# STM32WBA65 register map
File version: 1.0
CPU: CM33 r0p1, little endian, MPU, FPU, 4 interrupt priority bits
Registers are 32-bit, read-write, reset 0x0 unless marked. A register's access mark holds for its fields unless they carry their own. Offsets are from the block's base; [hi:lo] are bit positions.

## GTZC_TZSC — GTZC_TZSC address block description
Base 0x40032400
Same registers: SEC_GTZC_TZSC 0x50032400
0x00 GTZC1_TZSC_CR — GTZC1 TZSC control register
  [0] LCK — Lock the configuration of GTZC1_TZSC_SECCFGRn and GTZC1_TZSC_PRIVCFGRn registers until next reset
    0=Configuration of all GTZC1_TZSC_SECCFGRn and GTZC1_TZSC_PRIVCFGRn registers not locked; 1=Configuration of all GTZC1_TZSC_SECCFGRn and GTZC1_TZSC_PRIVCFGRn registers locked
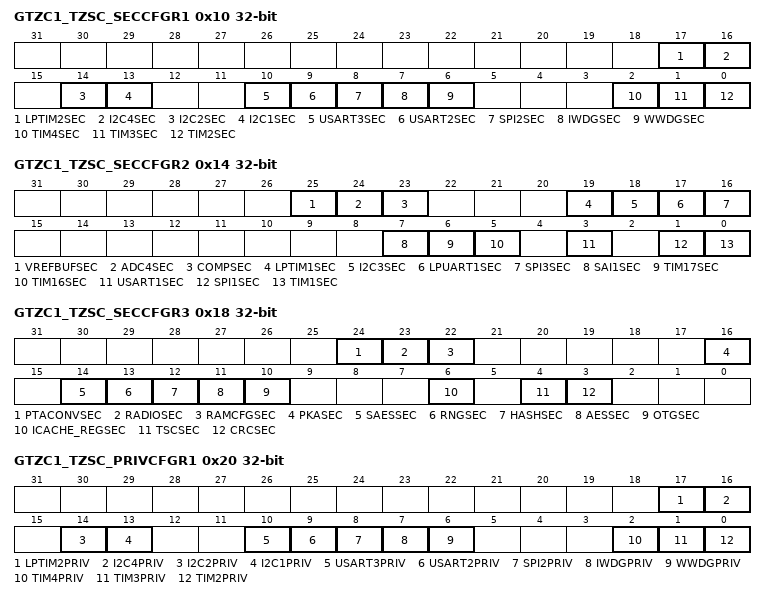
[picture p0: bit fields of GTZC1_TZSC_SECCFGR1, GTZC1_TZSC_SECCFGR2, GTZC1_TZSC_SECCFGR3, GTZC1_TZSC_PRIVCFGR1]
0x10 GTZC1_TZSC_SECCFGR1 — GTZC1 TZSC secure configuration register 1
  [all] fields
    0=Nonsecure; 1=Secure
  [17] LPTIM2SEC — Secure access mode for LPTIM2
  [16] I2C4SEC — Secure access mode for I2C4
  [14] I2C2SEC — Secure access mode for I2C2
  [13] I2C1SEC — Secure access mode for I2C1
  [10] USART3SEC — Secure access mode for USART3
  [9] USART2SEC — Secure access mode for USART2
  [8] SPI2SEC — Secure access mode for SPI2
  [7] IWDGSEC — Secure access mode for IWDG
  [6] WWDGSEC — Secure access mode for WWDG
  [2] TIM4SEC — Secure access mode for TIM4
  [1] TIM3SEC — Secure access mode for TIM3
  [0] TIM2SEC — Secure access mode for TIM2
0x14 GTZC1_TZSC_SECCFGR2 — GTZC1 TZSC secure configuration register 2
  [all] fields
    0=Nonsecure; 1=Secure
  [25] VREFBUFSEC — Secure access mode for VREFBUF
  [24] ADC4SEC — Secure access mode for ADC4
  [23] COMPSEC — Secure access mode for COMP
  [19] LPTIM1SEC — Secure access mode for LPTIM1
  [18] I2C3SEC — Secure access mode for I2C3
  [17] LPUART1SEC — Secure access mode for LPUART1
  [16] SPI3SEC — Secure access mode for SPI3
  [7] SAI1SEC — Secure access mode for SAI1
  [6] TIM17SEC — Secure access mode for TIM17
  [5] TIM16SEC — Secure access mode for TIM16
  [3] USART1SEC — Secure access mode for USART1
  [1] SPI1SEC — Secure access mode for SPI1
  [0] TIM1SEC — Secure access mode for TIM1
0x18 GTZC1_TZSC_SECCFGR3 — GTZC1 TZSC secure configuration register 3
  [all] fields
    0=Nonsecure; 1=Secure
  [24] PTACONVSEC — Secure access mode for PTACONV
  [23] RADIOSEC — Secure access mode for 2.
  [22] RAMCFGSEC — Secure access mode for RAMCFG
  [16] PKASEC — Secure access mode for PKA
  [14] SAESSEC — Secure access mode for SAES
  [13] RNGSEC — Secure access mode for RNG
  [12] HASHSEC — Secure access mode for HASH
  [11] AESSEC — Secure access mode for AES
  [10] OTGSEC — Secure access mode for USB OTG_HS
  [6] ICACHE_REGSEC — Secure access mode for ICACHE registers
  [4] TSCSEC — Secure access mode for TSC
  [3] CRCSEC — Secure access mode for CRC
0x20 GTZC1_TZSC_PRIVCFGR1 — GTZC1 TZSC privilege configuration register 1
  [all] fields
    0=Unprivileged; 1=Privileged
  [17] LPTIM2PRIV — Privileged access mode for LPTIM2
  [16] I2C4PRIV — Privileged access mode for I2C4
  [14] I2C2PRIV — Privileged access mode for I2C2
  [13] I2C1PRIV — Privileged access mode for I2C1
  [10] USART3PRIV — Privileged access mode for USART3
  [9] USART2PRIV — Privileged access mode for USART2
  [8] SPI2PRIV — Privileged access mode for SPI2
  [7] IWDGPRIV — Privileged access mode for IWDG
  [6] WWDGPRIV — Privileged access mode for WWDG
  [2] TIM4PRIV — Privileged access mode for TIM4
  [1] TIM3PRIV — Privileged access mode for TIM3
  [0] TIM2PRIV — Privileged access mode for TIM2
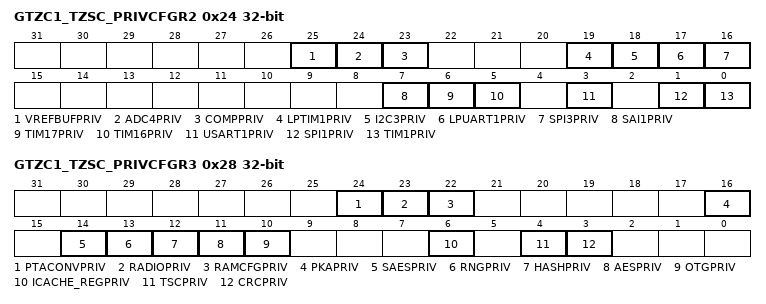
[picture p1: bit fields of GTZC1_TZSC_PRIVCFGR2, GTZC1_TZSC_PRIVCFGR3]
0x24 GTZC1_TZSC_PRIVCFGR2 — GTZC1 TZSC privilege configuration register 2
  [all] fields
    0=Unprivileged; 1=Privileged
  [25] VREFBUFPRIV — Privileged access mode for VREFBUF
  [24] ADC4PRIV — Privileged access mode for ADC4
  [23] COMPPRIV — Privileged access mode for COMP
  [19] LPTIM1PRIV — Privileged access mode for LPTIM1
  [18] I2C3PRIV — Privileged access mode for I2C3
  [17] LPUART1PRIV — Privileged access mode for LPUART1
  [16] SPI3PRIV — Privileged access mode for SPI3
  [7] SAI1PRIV — Privileged access mode for SAI1
  [6] TIM17PRIV — Privileged access mode for TIM17
  [5] TIM16PRIV — Privileged access mode for TIM16
  [3] USART1PRIV — Privileged access mode for USART1
  [1] SPI1PRIV — Privileged access mode for SPI1PRIV
  [0] TIM1PRIV — Privileged access mode for TIM1
0x28 GTZC1_TZSC_PRIVCFGR3 — GTZC1 TZSC privilege configuration register 3
  [all] fields
    0=Unprivileged; 1=Privileged
  [24] PTACONVPRIV — Privileged access mode for PTACONV
  [23] RADIOPRIV — Privileged access mode for 2.
  [22] RAMCFGPRIV — Privileged access mode for RAMCFG
  [16] PKAPRIV — Privileged access mode for PKA
  [14] SAESPRIV — Privileged access mode for SAES
  [13] RNGPRIV — Privileged access mode for RNG
  [12] HASHPRIV — Privileged access mode for HASH
  [11] AESPRIV — Privileged access mode for AES
  [10] OTGPRIV — Privileged access mode for USB OTG_HS
  [6] ICACHE_REGPRIV — Privileged access mode for ICACHE registers
  [4] TSCPRIV — Privileged access mode for TSC
  [3] CRCPRIV — Privileged access mode for CRC

## Notices in the file
Copyright (c) 2025 STMicroelectronics.
SPDX-License-Identifier: Apache-2.0
Licensed under the Apache License, Version 2.0 (the "License");
you may not use this file except in compliance with the License.
You may obtain a copy of the License at
http://www.apache.org/licenses/LICENSE-2.0
Unless required by applicable law or agreed to in writing, software
distributed under the License is distributed on an "AS IS" BASIS,
WITHOUT WARRANTIES OR CONDITIONS OF ANY KIND, either express or implied.
See the License for the specific language governing permissions and
limitations under the License.
